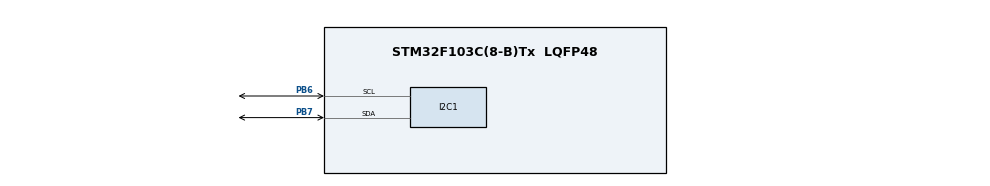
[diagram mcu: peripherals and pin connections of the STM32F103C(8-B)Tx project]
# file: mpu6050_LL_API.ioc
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Dma.I2C1_TX.0.Direction=DMA_MEMORY_TO_PERIPH
Dma.I2C1_TX.0.Instance=DMA1_Channel6
Dma.I2C1_TX.0.MemDataAlignment=DMA_MDATAALIGN_BYTE
Dma.I2C1_TX.0.MemInc=DMA_MINC_ENABLE
Dma.I2C1_TX.0.Mode=DMA_NORMAL
Dma.I2C1_TX.0.PeriphDataAlignment=DMA_PDATAALIGN_BYTE
Dma.I2C1_TX.0.PeriphInc=DMA_PINC_DISABLE
Dma.I2C1_TX.0.Priority=DMA_PRIORITY_LOW
Dma.Request0=I2C1_TX
Mcu.Family=STM32F1
Mcu.Name=STM32F103C(8-B)Tx
Mcu.Package=LQFP48
NVIC.DMA1_Channel6_IRQn=true\:0\:0\:false\:false\:true\:false\:true\:true
NVIC.I2C1_ER_IRQn=true\:0\:0\:false\:false\:true\:true\:true\:true
NVIC.I2C1_EV_IRQn=true\:0\:0\:false\:false\:true\:true\:true\:true
NVIC.PriorityGroup=NVIC_PRIORITYGROUP_4
PA13.Mode=Serial_Wire
PA13.Signal=SYS_JTMS-SWDIO
PA14.Mode=Serial_Wire
PA14.Signal=SYS_JTCK-SWCLK
PB6.GPIO_Pu=GPIO_PULLUP
PB6.Mode=I2C
PB6.Signal=I2C1_SCL
PB7.GPIO_Pu=GPIO_PULLUP
PB7.Mode=I2C
PB7.Signal=I2C1_SDA
PD0-OSC_IN.Mode=HSE-External-Oscillator
PD0-OSC_IN.Signal=RCC_OSC_IN
PD1-OSC_OUT.Mode=HSE-External-Oscillator
PD1-OSC_OUT.Signal=RCC_OSC_OUT
ProjectManager.HeapSize=0x200
ProjectManager.StackSize=0x400
ProjectManager.TargetToolchain=STM32CubeIDE
RCC.AHBFreq_Value=72000000
RCC.APB1CLKDivider=RCC_HCLK_DIV2
RCC.APB1Freq_Value=36000000
RCC.APB1TimFreq_Value=72000000
RCC.APB2Freq_Value=72000000
RCC.APB2TimFreq_Value=72000000
RCC.HCLKFreq_Value=72000000
RCC.PLLMUL=RCC_PLL_MUL9
RCC.PLLSourceVirtual=RCC_PLLSOURCE_HSE
RCC.SYSCLKFreq_VALUE=72000000
RCC.SYSCLKSource=RCC_SYSCLKSOURCE_PLLCLK
RCC.USBFreq_Value=72000000
board=custom

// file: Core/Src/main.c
/* USER CODE BEGIN Header */
/**
  ******************************************************************************
  * @file           : main.c
  * @brief          : Main program body
  ******************************************************************************
  * @attention
  *
  * Copyright (c) 2023 STMicroelectronics.
  * All rights reserved.
  *
  * This software is licensed under terms that can be found in the LICENSE file
  * in the root directory of this software component.
  * If no LICENSE file comes with this software, it is provided AS-IS.
  *
  ******************************************************************************
  */
/* USER CODE END Header */
#include "main.h"
#include "dma.h"
#include "i2c.h"
#include "gpio.h"

void SystemClock_Config(void);

/* USER CODE BEGIN 0 */

#define MPU6050_ADDR 0xD0
#define SMPLRT_DIV_REG 0x19
#define GYRO_CONFIG_REG 0x1B
#define ACCEL_CONFIG_REG 0x1C
#define ACCEL_XOUT_H_REG 0x3B
#define TEMP_OUT_H_REG 0x41
#define GYRO_XOUT_H_REG 0x43
#define PWR_MGMT_1_REG 0x6B
#define WHO_AM_I_REG 0x75

int16_t Accel_X_RAW = 0;
int16_t Accel_Y_RAW = 0;
int16_t Accel_Z_RAW = 0;

int16_t Gyro_X_RAW = 0;
int16_t Gyro_Y_RAW = 0;
int16_t Gyro_Z_RAW = 0;

float Ax, Ay, Az, Gx, Gy, Gz;

/* USER CODE END 0 */

int main(void)
{

  /* MCU Configuration--------------------------------------------------------*/

  /* Reset of all peripherals, Initializes the Flash interface and the Systick. */
  LL_APB2_GRP1_EnableClock(LL_APB2_GRP1_PERIPH_AFIO);
  LL_APB1_GRP1_EnableClock(LL_APB1_GRP1_PERIPH_PWR);

  /* System interrupt init*/
  NVIC_SetPriorityGrouping(NVIC_PRIORITYGROUP_4);

  /** NOJTAG: JTAG-DP Disabled and SW-DP Enabled
  */
  LL_GPIO_AF_Remap_SWJ_NOJTAG();

  /* Configure the system clock */
  SystemClock_Config();

  /* Initialize all configured peripherals */
  MX_GPIO_Init();
  MX_DMA_Init();
  MX_I2C1_Init();

  /* USER CODE BEGIN 2 */

  uint8_t rxtest[1]={0};

  // Check device ID
  //
  I2C_SendRequest( MPU6050_ADDR, WHO_AM_I_REG, rxtest, 1 );
  LL_mDelay(100);

  //if ( rxtest[0] == 104 ) {

	  // Wake up the sensor
	  //
	  I2C_WriteRequest( MPU6050_ADDR, PWR_MGMT_1_REG, 0x00 );
	  LL_mDelay(20);

	  // Set DATA RATE of 1KHz by writing SMPLRT_DIV register
	  //
	  I2C_WriteRequest( MPU6050_ADDR, SMPLRT_DIV_REG, 0x07 );
	  LL_mDelay(20);

	  // Set accelerometer configuration in ACCEL_CONFIG Register
	  // XA_ST=0,YA_ST=0,ZA_ST=0, FS_SEL=0 -> ± 2g
	  //
	  I2C_WriteRequest( MPU6050_ADDR, ACCEL_CONFIG_REG, 0x00 );
	  LL_mDelay(20);

	  // Set Gyroscopic configuration in GYRO_CONFIG Register
	  // XG_ST=0,YG_ST=0,ZG_ST=0, FS_SEL=0 -> ± 250 °/s
	  //
	  I2C_WriteRequest( MPU6050_ADDR, GYRO_CONFIG_REG, 0x00 );
	  LL_mDelay(20);

  //}

  /* USER CODE END 2 */

  /* Infinite loop */

  /* USER CODE BEGIN WHILE */

  __NOP();
  uint8_t Rec_Data[6];

  while (1)
  {

	// Read accelerations --- //

	I2C_SendRequest( MPU6050_ADDR, ACCEL_XOUT_H_REG, Rec_Data, 6 );

	Accel_X_RAW = (int16_t)(Rec_Data[0] << 8 | Rec_Data [1]);
	Accel_Y_RAW = (int16_t)(Rec_Data[2] << 8 | Rec_Data [3]);
	Accel_Z_RAW = (int16_t)(Rec_Data[4] << 8 | Rec_Data [5]);

	__NOP();

	// Convert the RAW values into acceleration in 'g'
	// we have to divide according to the Full scale value set in FS_SEL
	// I have configured FS_SEL = 0. So I am dividing by 16384.0
	// for more details check ACCEL_CONFIG Register

	Ax = Accel_X_RAW/16384.0;
	Ay = Accel_Y_RAW/16384.0;
	Az = Accel_Z_RAW/16384.0;

	LL_mDelay(200);
	// End read accelerations --- //

    /* USER CODE END WHILE */

  }
}

void SystemClock_Config(void)
{
  LL_FLASH_SetLatency(LL_FLASH_LATENCY_2);
  while(LL_FLASH_GetLatency()!= LL_FLASH_LATENCY_2)
  {
  }
  LL_RCC_HSE_Enable();

   /* Wait till HSE is ready */
  while(LL_RCC_HSE_IsReady() != 1)
  {

  }
  LL_RCC_PLL_ConfigDomain_SYS(LL_RCC_PLLSOURCE_HSE_DIV_1, LL_RCC_PLL_MUL_9);
  LL_RCC_PLL_Enable();

   /* Wait till PLL is ready */
  while(LL_RCC_PLL_IsReady() != 1)
  {

  }
  LL_RCC_SetAHBPrescaler(LL_RCC_SYSCLK_DIV_1);
  LL_RCC_SetAPB1Prescaler(LL_RCC_APB1_DIV_2);
  LL_RCC_SetAPB2Prescaler(LL_RCC_APB2_DIV_1);
  LL_RCC_SetSysClkSource(LL_RCC_SYS_CLKSOURCE_PLL);

   /* Wait till System clock is ready */
  while(LL_RCC_GetSysClkSource() != LL_RCC_SYS_CLKSOURCE_STATUS_PLL)
  {

  }
  LL_Init1msTick(72000000);
  LL_SetSystemCoreClock(72000000);
}

void Error_Handler(void)
{
  __disable_irq();
  while (1)
  {
  }
}
